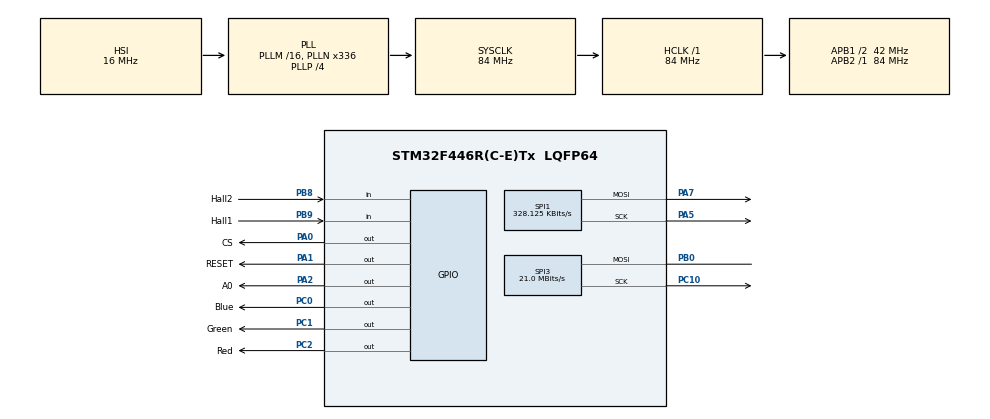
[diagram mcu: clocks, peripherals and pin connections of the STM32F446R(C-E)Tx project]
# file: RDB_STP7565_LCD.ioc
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Mcu.Family=STM32F4
Mcu.Name=STM32F446R(C-E)Tx
Mcu.Package=LQFP64
NVIC.PriorityGroup=NVIC_PRIORITYGROUP_0
PA0-WKUP.GPIO_Label=CS
PA0-WKUP.Signal=GPIO_Output
PA1.GPIO_Label=RESET
PA1.Signal=GPIO_Output
PA13.GPIO_Label=TMS
PA13.Mode=Serial_Wire
PA13.Signal=SYS_JTMS-SWDIO
PA14.GPIO_Label=TCK
PA14.Mode=Serial_Wire
PA14.Signal=SYS_JTCK-SWCLK
PA2.GPIO_Label=A0
PA2.Signal=GPIO_Output
PA3.GPIO_Label=USART_RX
PA3.Signal=USART2_RX
PA5.Mode=TX_Only_Simplex_Unidirect_Master
PA5.Signal=SPI1_SCK
PA7.Mode=TX_Only_Simplex_Unidirect_Master
PA7.Signal=SPI1_MOSI
PB0.Mode=Simplex_Bidirectional_Master
PB0.Signal=SPI3_MOSI
PB3.GPIO_Label=SWO
PB3.Signal=SYS_JTDO-SWO
PB8.GPIO_Label=Hall2
PB8.Signal=GPIO_Input
PB9.GPIO_Label=Hall1
PB9.Signal=GPIO_Input
PC0.GPIO_Label=Blue
PC0.Signal=GPIO_Output
PC1.GPIO_Label=Green
PC1.Signal=GPIO_Output
PC10.Mode=Simplex_Bidirectional_Master
PC10.Signal=SPI3_SCK
PC14-OSC32_IN.Mode=LSE-External-Oscillator
PC14-OSC32_IN.Signal=RCC_OSC32_IN
PC15-OSC32_OUT.Mode=LSE-External-Oscillator
PC15-OSC32_OUT.Signal=RCC_OSC32_OUT
PC2.GPIO_Label=Red
PC2.Signal=GPIO_Output
PH0-OSC_IN.Mode=HSE-External-Oscillator
PH0-OSC_IN.Signal=RCC_OSC_IN
PH1-OSC_OUT.Mode=HSE-External-Oscillator
PH1-OSC_OUT.Signal=RCC_OSC_OUT
ProjectManager.HeapSize=0x200
ProjectManager.StackSize=0x400
ProjectManager.TargetToolchain=STM32CubeIDE
RCC.48MHZClocksFreq_Value=84000000
RCC.AHBFreq_Value=84000000
RCC.APB1CLKDivider=RCC_HCLK_DIV2
RCC.APB1Freq_Value=42000000
RCC.APB1TimFreq_Value=84000000
RCC.APB2Freq_Value=84000000
RCC.APB2TimFreq_Value=84000000
RCC.CortexFreq_Value=84000000
RCC.FLatency-AdvancedSettings=FLASH_LATENCY_2
RCC.HCLKFreq_Value=84000000
RCC.HSE_VALUE=8000000
RCC.HSI_VALUE=16000000
RCC.PLLN=336
RCC.PLLP=RCC_PLLP_DIV4
RCC.SYSCLKFreq_VALUE=84000000
RCC.SYSCLKSource=RCC_SYSCLKSOURCE_PLLCLK
RCC.USBFreq_Value=168000000
RCC.VCOOutputFreq_Value=336000000
SPI1.BaudRatePrescaler=SPI_BAUDRATEPRESCALER_256
SPI1.CalculateBaudRate=328.125 KBits/s
SPI1.Direction=SPI_DIRECTION_2LINES
SPI1.Mode=SPI_MODE_MASTER
SPI1.VirtualType=VM_MASTER
SPI3.CalculateBaudRate=21.0 MBits/s
SPI3.Direction=SPI_DIRECTION_1LINE
SPI3.Mode=SPI_MODE_MASTER
SPI3.VirtualType=VM_MASTER
board=NUCLEO-F446RE

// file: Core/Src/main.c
/* USER CODE BEGIN Header */
/**
  ******************************************************************************
  * @file           : main.c
  * @brief          : Main program body
  ******************************************************************************
  * @attention
  *
  * Copyright (c) 2025 STMicroelectronics.
  * All rights reserved.
  *
  * This software is licensed under terms that can be found in the LICENSE file
  * in the root directory of this software component.
  * If no LICENSE file comes with this software, it is provided AS-IS.
  *
  ******************************************************************************
  */
/* USER CODE END Header */
#include <RDB_Depth_Digits_64.h>
#include "main.h"

/* USER CODE BEGIN Includes */
#include<string.h>
#include"ST7565.h"
#include"RDB_depth_digits_36x58.h"
#include"RDB_Functions.h"
/* USER CODE END Includes */

SPI_HandleTypeDef hspi1;
SPI_HandleTypeDef hspi3;

/* USER CODE BEGIN PV */
extern uint8_t displayBuffer[LCD_WIDTH*LCD_HEIGHT/8];
int count = 0;

/* USER CODE END PV */

void SystemClock_Config(void);
static void MX_GPIO_Init(void);
static void MX_SPI1_Init(void);
static void MX_SPI3_Init(void);

int main(void)
{

  /* MCU Configuration--------------------------------------------------------*/

  /* Reset of all peripherals, Initializes the Flash interface and the Systick. */
  HAL_Init();

  /* Configure the system clock */
  SystemClock_Config();

  /* Initialize all configured peripherals */
  MX_GPIO_Init();
  MX_SPI1_Init();
  MX_SPI3_Init();
  /* USER CODE BEGIN 2 */
  HAL_GPIO_WritePin(GPIOB, RESET_Pin, GPIO_PIN_RESET);
  HAL_Delay(1);
  HAL_GPIO_WritePin(GPIOB, RESET_Pin, GPIO_PIN_SET);
  HAL_Delay(10);

  ST7565_init();

  /* USER CODE END 2 */

  /* Infinite loop */
  /* USER CODE BEGIN WHILE */
  while (1)
  {

   //countTestRDBlcd();

   parseDepthVal(count);
   count ++;
   if(count > 200){
	   count = 0;
   }
   HAL_Delay(100);
	  ST7565_drawstring_anywhere(0, 7, "DEPTH"); // x=pixel,y=page
	  ST7565_drawstring_anywhere(115, 0, "ft");  //

	  updateDisplay();
  }
  /* USER CODE END 3 */
}

void SystemClock_Config(void)
{
  RCC_OscInitTypeDef RCC_OscInitStruct = {0};
  RCC_ClkInitTypeDef RCC_ClkInitStruct = {0};

  /** Configure the main internal regulator output voltage
  */
  __HAL_RCC_PWR_CLK_ENABLE();
  __HAL_PWR_VOLTAGESCALING_CONFIG(PWR_REGULATOR_VOLTAGE_SCALE3);

  /** Initializes the RCC Oscillators according to the specified parameters
  * in the RCC_OscInitTypeDef structure.
  */
  RCC_OscInitStruct.OscillatorType = RCC_OSCILLATORTYPE_HSI;
  RCC_OscInitStruct.HSIState = RCC_HSI_ON;
  RCC_OscInitStruct.HSICalibrationValue = RCC_HSICALIBRATION_DEFAULT;
  RCC_OscInitStruct.PLL.PLLState = RCC_PLL_ON;
  RCC_OscInitStruct.PLL.PLLSource = RCC_PLLSOURCE_HSI;
  RCC_OscInitStruct.PLL.PLLM = 16;
  RCC_OscInitStruct.PLL.PLLN = 336;
  RCC_OscInitStruct.PLL.PLLP = RCC_PLLP_DIV4;
  RCC_OscInitStruct.PLL.PLLQ = 2;
  RCC_OscInitStruct.PLL.PLLR = 2;
  if (HAL_RCC_OscConfig(&RCC_OscInitStruct) != HAL_OK)
  {
    Error_Handler();
  }

  /** Initializes the CPU, AHB and APB buses clocks
  */
  RCC_ClkInitStruct.ClockType = RCC_CLOCKTYPE_HCLK|RCC_CLOCKTYPE_SYSCLK
                              |RCC_CLOCKTYPE_PCLK1|RCC_CLOCKTYPE_PCLK2;
  RCC_ClkInitStruct.SYSCLKSource = RCC_SYSCLKSOURCE_PLLCLK;
  RCC_ClkInitStruct.AHBCLKDivider = RCC_SYSCLK_DIV1;
  RCC_ClkInitStruct.APB1CLKDivider = RCC_HCLK_DIV2;
  RCC_ClkInitStruct.APB2CLKDivider = RCC_HCLK_DIV1;

  if (HAL_RCC_ClockConfig(&RCC_ClkInitStruct, FLASH_LATENCY_2) != HAL_OK)
  {
    Error_Handler();
  }
}

static void MX_SPI1_Init(void)
{

  /* SPI1 parameter configuration*/
  hspi1.Instance = SPI1;
  hspi1.Init.Mode = SPI_MODE_MASTER;
  hspi1.Init.Direction = SPI_DIRECTION_2LINES;
  hspi1.Init.DataSize = SPI_DATASIZE_8BIT;
  hspi1.Init.CLKPolarity = SPI_POLARITY_LOW;
  hspi1.Init.CLKPhase = SPI_PHASE_1EDGE;
  hspi1.Init.NSS = SPI_NSS_SOFT;
  hspi1.Init.BaudRatePrescaler = SPI_BAUDRATEPRESCALER_256;
  hspi1.Init.FirstBit = SPI_FIRSTBIT_MSB;
  hspi1.Init.TIMode = SPI_TIMODE_DISABLE;
  hspi1.Init.CRCCalculation = SPI_CRCCALCULATION_DISABLE;
  hspi1.Init.CRCPolynomial = 10;
  if (HAL_SPI_Init(&hspi1) != HAL_OK)
  {
    Error_Handler();
  }

}

static void MX_SPI3_Init(void)
{

  /* SPI3 parameter configuration*/
  hspi3.Instance = SPI3;
  hspi3.Init.Mode = SPI_MODE_MASTER;
  hspi3.Init.Direction = SPI_DIRECTION_1LINE;
  hspi3.Init.DataSize = SPI_DATASIZE_8BIT;
  hspi3.Init.CLKPolarity = SPI_POLARITY_LOW;
  hspi3.Init.CLKPhase = SPI_PHASE_1EDGE;
  hspi3.Init.NSS = SPI_NSS_SOFT;
  hspi3.Init.BaudRatePrescaler = SPI_BAUDRATEPRESCALER_2;
  hspi3.Init.FirstBit = SPI_FIRSTBIT_MSB;
  hspi3.Init.TIMode = SPI_TIMODE_DISABLE;
  hspi3.Init.CRCCalculation = SPI_CRCCALCULATION_DISABLE;
  hspi3.Init.CRCPolynomial = 10;
  if (HAL_SPI_Init(&hspi3) != HAL_OK)
  {
    Error_Handler();
  }

}

static void MX_GPIO_Init(void)
{
  GPIO_InitTypeDef GPIO_InitStruct = {0};

  /* GPIO Ports Clock Enable */
  __HAL_RCC_GPIOC_CLK_ENABLE();
  __HAL_RCC_GPIOH_CLK_ENABLE();
  __HAL_RCC_GPIOA_CLK_ENABLE();
  __HAL_RCC_GPIOB_CLK_ENABLE();

  /*Configure GPIO pin Output Level */
  HAL_GPIO_WritePin(GPIOC, Blue_Pin|Green_Pin|Red_Pin, GPIO_PIN_RESET);

  /*Configure GPIO pin Output Level */
  HAL_GPIO_WritePin(GPIOA, CS_Pin|RESET_Pin|A0_Pin, GPIO_PIN_RESET);

  /*Configure GPIO pins : Blue_Pin Green_Pin Red_Pin */
  GPIO_InitStruct.Pin = Blue_Pin|Green_Pin|Red_Pin;
  GPIO_InitStruct.Mode = GPIO_MODE_OUTPUT_PP;
  GPIO_InitStruct.Pull = GPIO_NOPULL;
  GPIO_InitStruct.Speed = GPIO_SPEED_FREQ_LOW;
  HAL_GPIO_Init(GPIOC, &GPIO_InitStruct);

  /*Configure GPIO pins : CS_Pin RESET_Pin A0_Pin */
  GPIO_InitStruct.Pin = CS_Pin|RESET_Pin|A0_Pin;
  GPIO_InitStruct.Mode = GPIO_MODE_OUTPUT_PP;
  GPIO_InitStruct.Pull = GPIO_NOPULL;
  GPIO_InitStruct.Speed = GPIO_SPEED_FREQ_LOW;
  HAL_GPIO_Init(GPIOA, &GPIO_InitStruct);

  /*Configure GPIO pin : USART_RX_Pin */
  GPIO_InitStruct.Pin = USART_RX_Pin;
  GPIO_InitStruct.Mode = GPIO_MODE_AF_PP;
  GPIO_InitStruct.Pull = GPIO_NOPULL;
  GPIO_InitStruct.Speed = GPIO_SPEED_FREQ_VERY_HIGH;
  GPIO_InitStruct.Alternate = GPIO_AF7_USART2;
  HAL_GPIO_Init(USART_RX_GPIO_Port, &GPIO_InitStruct);

  /*Configure GPIO pins : Hall2_Pin Hall1_Pin */
  GPIO_InitStruct.Pin = Hall2_Pin|Hall1_Pin;
  GPIO_InitStruct.Mode = GPIO_MODE_INPUT;
  GPIO_InitStruct.Pull = GPIO_NOPULL;
  HAL_GPIO_Init(GPIOB, &GPIO_InitStruct);

}

void Error_Handler(void)
{
  __disable_irq();
  while (1)
  {
  }
}
